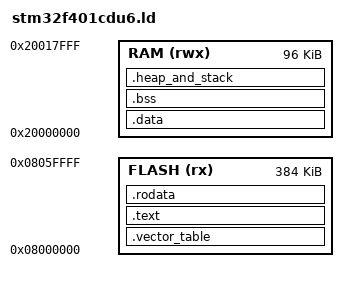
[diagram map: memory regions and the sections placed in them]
ENTRY(reset_handler)

_Min_Heap_Size = 0x200;
_Min_Stack_Size = 0x400;

MEMORY
{
  FLASH (rx) : ORIGIN = 0x08000000, LENGTH = 384K
  RAM (rwx) : ORIGIN = 0x20000000, LENGTH = 96K
}

_estack = ORIGIN(RAM) + LENGTH(RAM);

SECTIONS
{
  .vector_table :
  {
    . = ALIGN(4);
    KEEP(*(.vector_table))
    . = ALIGN(4);
  } >FLASH

  .text :
  {
    . = ALIGN(4);
    *(.text)
    *(.text*)
    . = ALIGN(4);
  } >FLASH

  .rodata :
  {
    . = ALIGN(4);
    *(.rodata)
    *(.rodata*)
    . = ALIGN(4);
  } >FLASH

  _sidata = .;
  .data : AT(_sidata)
  {
    . = ALIGN(4);
    _sdata = .;
    *(.data)
    *(.data*)
    . = ALIGN(4);
    _edata = .;
  } >RAM

  .bss :
  {
    . = ALIGN(4);
    _sbss = .;
    *(.bss)
    *(.bss*)
    *(COMMON)
    . = ALIGN(4);
    _ebss = .;
  } >RAM

  .heap_and_stack :
  {
    . = ALIGN(4);
    _ssys_ram = .;
    . = . + _Min_Heap_Size;
    . = . + _Min_Stack_Size;
    . = ALIGN(4);
    _esys_ram = .;
  } >RAM
}
